# HDSC_HC32M424 register map
Vendor: HDSC; Series: ARMCM4; File version: 1.0
CPU: CM4 r0p1, little endian, MPU, FPU, 4 interrupt priority bits
Registers are 32-bit, read-write, reset 0x0 unless marked. A register's access mark holds for its fields unless they carry their own. Offsets are from the block's base; lines under a group give offsets from that group; [hi:lo] are bit positions; {n}, {i} and the like mark numbered series; 'fields as' and 'values as' point back to an identical list; <NAME> marks a mode.

## Memory map
0x000002C0 ICG size 0x20
0x40010400 EFM size 0x289
0x40010800 AOS size 0xB4
0x40015000 TMRA1 size 0x146 — desc TMRA
0x40015400 TMRA2 size 0x146 — desc TMRA
0x40015800 TMRA3 size 0x146 — desc TMRA
0x40015C00 TMRA4 size 0x146 — desc TMRA
0x40016000 TMRA5 size 0x146 — desc TMRA
0x40016400 TMRA6 size 0x146 — desc TMRA
0x40017000 TMR41 size 0xE2 — desc TMR4
0x40017400 TMR42 size 0xE2 — desc TMR4
0x40017C00 EMB0 size 0x1C — desc EMB
0x40017C20 EMB1 size 0x1C — desc EMB
0x40017C40 EMB2 size 0x20 — desc EMB
0x40017C60 EMB3 size 0x20 — desc EMB
0x4001C000 SPI size 0x1C
0x4001D000 USART1 size 0x1C — desc USART
0x4001D400 USART2 size 0x1C — desc USART
0x40021000 USART3 size 0x1C — desc USART
0x40021400 USART4 size 0x1C — desc USART
0x40024000 TMR01 size 0x18 — desc TMR0
0x40024400 TMR02 size 0x18 — desc TMR0
0x40025000 TMRB1 size 0x150 — desc TMRB
0x40025400 TMRB2 size 0x150 — desc TMRB
0x40025800 TMRB3 size 0x150 — desc TMRB
0x40030000 ADC1 size 0xB1
0x40030400 ADC2 size 0xB1
0x40030800 ADC3 size 0xB1
0x40040000 CTC size 0xE
0x40048400 FCM size 0x24
0x40049400 SWDT size 0xC
0x4004A000 CMP1 size 0x6 — desc CMP
0x4004A010 CMP2 size 0x6 — desc CMP
0x4004A020 CMP3 size 0x6 — desc CMP
0x4004A030 CMP4 size 0x6 — desc CMP
0x4004A100 CMPCR size 0x19
0x4004E000 I2C size 0x34
0x40050400 CRC size 0x100
0x40051000 INTC size 0x80C
0x40052000 DCU size 0x1C
0x40053000 DMA size 0x210
0x40053800 GPIO size 0x5D8
0x40054000 PWC size 0x42
0x40054100 RMU size 0x2
0x40054400 CMU size 0x49
0xE0042000 DBGC size 0x1C

## ADC1
Base 0x40030000
0x00 STR 8-bit
  [0] STRT
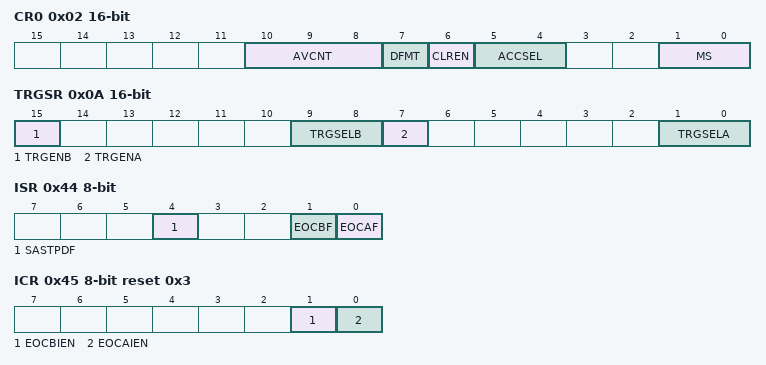
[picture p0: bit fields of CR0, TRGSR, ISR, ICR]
0x02 CR0 16-bit
  [10:8] AVCNT, [7] DFMT, [6] CLREN, [5:4] ACCSEL, [1:0] MS
0x04 CR1 16-bit
  [2] RSCHSEL
0x0A TRGSR 16-bit
  [15] TRGENB, [9:8] TRGSELB, [7] TRGENA, [1:0] TRGSELA
0x0C CHSELRA0 16-bit
  [4:0] CHSELA
0x10 CHSELRB0 16-bit
  [4:0] CHSELB
0x14 AVCHSELR0 16-bit
  [4:0] AVCHSEL
0x18 EXCHSELR 8-bit
  [0] EXCHSEL
{0x20+i} SSTR{i} 8-bit reset 0xB (i=0..4)
0x44 ISR 8-bit ro
  [4] SASTPDF, [1] EOCBF, [0] EOCAF
0x45 ICR 8-bit reset 0x3
  [1] EOCBIEN, [0] EOCAIEN
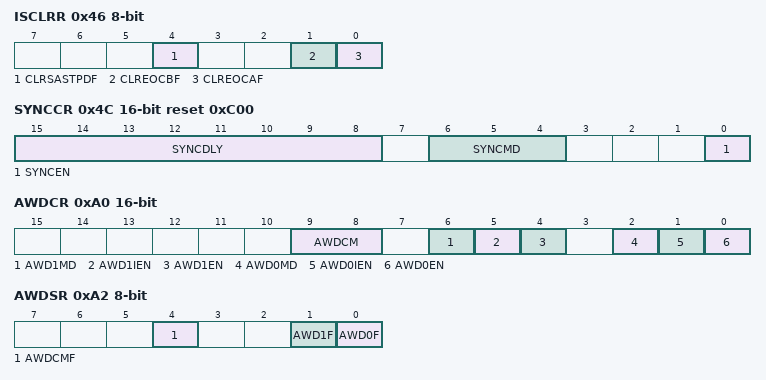
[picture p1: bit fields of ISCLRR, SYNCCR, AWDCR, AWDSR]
0x46 ISCLRR 8-bit wo
  [4] CLRSASTPDF, [1] CLREOCBF, [0] CLREOCAF
0x4C SYNCCR 16-bit reset 0xC00
  [15:8] SYNCDLY, [6:4] SYNCMD, [0] SYNCEN
{0x50+2i} DR{i} 16-bit ro (i=0..4)
0xA0 AWDCR 16-bit
  [9:8] AWDCM, [6] AWD1MD, [5] AWD1IEN, [4] AWD1EN, [2] AWD0MD, [1] AWD0IEN, [0] AWD0EN
0xA2 AWDSR 8-bit ro
  [4] AWDCMF, [1] AWD1F, [0] AWD0F
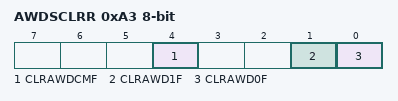
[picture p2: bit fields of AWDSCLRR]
0xA3 AWDSCLRR 8-bit
  [4] CLRAWDCMF, [1] CLRAWD1F, [0] CLRAWD0F
0xA4 AWD0DR0 16-bit
0xA6 AWD0DR1 16-bit reset 0xFFFF
0xA8 AWD0CHSR 8-bit
  [2:0] AWDCH
0xAC AWD1DR0 16-bit
0xAE AWD1DR1 16-bit reset 0xFFFF
0xB0 AWD1CHSR 8-bit
  [2:0] AWDCH

## ADC2
Base 0x40030400
Registers as ADC1, without SYNCCR; these are added or differ:
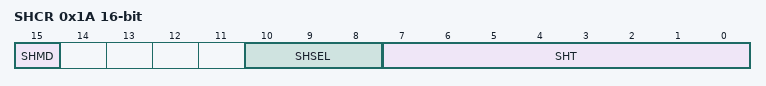
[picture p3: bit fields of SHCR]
0x1A SHCR 16-bit
  [15] SHMD, [10:8] SHSEL, [7:0] SHT

## ADC3
Base 0x40030800
Registers as ADC1, without SYNCCR; these are added or differ:
0x0C CHSELRA0 16-bit
  [11:0] CHSELA
0x10 CHSELRB0 16-bit
  [11:0] CHSELB
0x14 AVCHSELR0 16-bit
  [11:0] AVCHSEL
{0x20+i} SSTR{i} 8-bit reset 0xB (i=5..11)
{0x50+2i} DR{i} 16-bit ro (i=5..11)
0xA8 AWD0CHSR 8-bit
  [3:0] AWDCH
0xB0 AWD1CHSR 8-bit
  [3:0] AWDCH

## AOS
Base 0x40010800
0x00 SWTRG wo
  [0] STRG
0x20 TMR0_HTSSR reset 0x1FF
  [8:0] TRGSEL
0x40 TMRA_HTSSR reset 0x1FF
  [8:0] TRGSEL
0x50 TMRB_HTSSR reset 0x1FF
  [8:0] TRGSEL
{0x58+8i} ADC{i}_ITRGSELR0 reset 0x1FF (i=1..3)
  [8:0] TRGSEL
0x64 ADC1_ITRGSELR1 reset 0x1FF
  [8:0] TRGSEL
0x6C ADC2_ITRGSELR1 reset 0x1FF
  [8:0] TRGSEL
0x7C ADC3_ITRGSELR1 reset 0x1FF
  [8:0] TRGSEL
{0x80+4i} DMA_TRGSEL{i} reset 0x1FF (i=0..7)
  [8:0] TRGSEL
0xA0 DCU_TRGSEL reset 0x1FF
  [8:0] TRGSEL
0xB0 TMR4_HTSSR reset 0x1FF
  [8:0] TRGSEL
